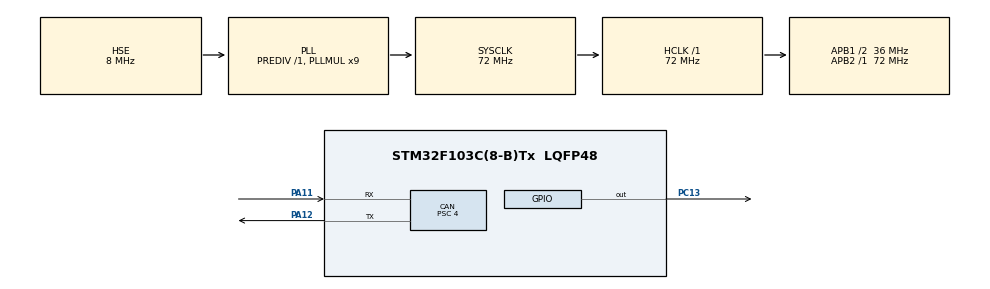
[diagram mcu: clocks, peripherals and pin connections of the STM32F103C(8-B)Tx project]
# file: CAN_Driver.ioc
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CAN.BS1=CAN_BS1_6TQ
CAN.BS2=CAN_BS2_2TQ
CAN.CalculateBaudRate=1000000
CAN.CalculateTimeBit=1000
CAN.CalculateTimeQuantum=111.11111111111111
CAN.Mode=CAN_MODE_NORMAL
CAN.Prescaler=4
CAN.TTCM=DISABLE
Mcu.Family=STM32F1
Mcu.Name=STM32F103C(8-B)Tx
Mcu.Package=LQFP48
NVIC.CAN1_RX1_IRQn=true\:0\:0\:false\:false\:true\:true\:true\:true
NVIC.PriorityGroup=NVIC_PRIORITYGROUP_4
NVIC.USB_LP_CAN1_RX0_IRQn=true\:1\:0\:true\:false\:true\:true\:true\:true
PA11.Mode=CAN_Activate
PA11.Signal=CAN_RX
PA12.Mode=CAN_Activate
PA12.Signal=CAN_TX
PA13.Mode=Serial_Wire
PA13.Signal=SYS_JTMS-SWDIO
PA14.Mode=Serial_Wire
PA14.Signal=SYS_JTCK-SWCLK
PC13-TAMPER-RTC.PinState=GPIO_PIN_SET
PC13-TAMPER-RTC.Signal=GPIO_Output
PD0-OSC_IN.Mode=HSE-External-Oscillator
PD0-OSC_IN.Signal=RCC_OSC_IN
PD1-OSC_OUT.Mode=HSE-External-Oscillator
PD1-OSC_OUT.Signal=RCC_OSC_OUT
ProjectManager.HeapSize=0x200
ProjectManager.StackSize=0x400
ProjectManager.TargetToolchain=MDK-ARM V5.32
RCC.AHBFreq_Value=72000000
RCC.APB1CLKDivider=RCC_HCLK_DIV2
RCC.APB1Freq_Value=36000000
RCC.APB1TimFreq_Value=72000000
RCC.APB2Freq_Value=72000000
RCC.APB2TimFreq_Value=72000000
RCC.HCLKFreq_Value=72000000
RCC.PLLMUL=RCC_PLL_MUL9
RCC.PLLSourceVirtual=RCC_PLLSOURCE_HSE
RCC.SYSCLKFreq_VALUE=72000000
RCC.SYSCLKSource=RCC_SYSCLKSOURCE_PLLCLK
RCC.USBFreq_Value=72000000
board=custom

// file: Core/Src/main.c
/* USER CODE BEGIN Header */
/**
  ******************************************************************************
  * @file           : main.c
  * @brief          : Main program body
  ******************************************************************************
  * @attention
  *
  * Copyright (c) 2025 STMicroelectronics.
  * All rights reserved.
  *
  * This software is licensed under terms that can be found in the LICENSE file
  * in the root directory of this software component.
  * If no LICENSE file comes with this software, it is provided AS-IS.
  *
  ******************************************************************************
  */
/* USER CODE END Header */
#include "main.h"
#include "can.h"
#include "gpio.h"

void SystemClock_Config(void);

/* USER CODE BEGIN 0 */
uint8_t flag=1;
float move,move_sum;
uint8_t tx_data[8]={1,2,3,4,5,6,7,8};
uint8_t rx_data[8]={0};
int16_t change=1;
int16_t target_angle=360;
struct Speed
{
  int16_t speed;
  volatile float Kp, Ki, Kd, Real, Out, Err0, Err1, ErrInt;
  volatile float Want;
};
struct Angle
{
  float angle,lastangle;
  volatile float Kp, Ki, Kd, Real, Out, Err0, Err1, ErrInt;
  volatile float Want;
};

struct Speed Speed_ctrl = {
  .speed = 0,
  .Kp = 8.4,
  .Ki = 1.2,
  .Kd = 30,
  .Real = 0,
  .Out = 0,
  .Err0 = 0,
  .Err1 = 0,
  .ErrInt = 0,
  .Want = 0
};

struct Angle Angle_ctrl = {
  .angle = 0,
  .lastangle = 0,
  .Kp = 10,
  .Ki = 0,
  .Kd = 5,
  .Real = 0,
  .Out = 0,
  .Err0 = 0,
  .Err1 = 0,
  .ErrInt = 0,
  .Want = 0
};

/* USER CODE END 0 */

int main(void)
{

  /* MCU Configuration--------------------------------------------------------*/

  /* Reset of all peripherals, Initializes the Flash interface and the Systick. */
  HAL_Init();

  /* Configure the system clock */
  SystemClock_Config();

  /* Initialize all configured peripherals */
  MX_GPIO_Init();
  MX_CAN_Init();
  /* USER CODE BEGIN 2 */
  // 在CAN初始化后启用FIFO0中断
if (HAL_CAN_ActivateNotification(&hcan, CAN_IT_RX_FIFO0_MSG_PENDING) != HAL_OK)
{
    Error_Handler();
}
if (HAL_CAN_ActivateNotification(&hcan, CAN_IT_RX_FIFO1_MSG_PENDING) != HAL_OK)
{
    Error_Handler();
}
  /* USER CODE END 2 */
  HAL_Delay(100);
  /* Infinite loop */
  /* USER CODE BEGIN WHILE */
  Angle_ctrl.Want=-720;
  while (1)
  {
    // if(Angle_ctrl.lastangle-Angle_ctrl.angle<-350)
    // {
    //   Angle_ctrl.Want+=360;
    // }

    /* USER CODE END WHILE */

  }
}

void SystemClock_Config(void)
{
  RCC_OscInitTypeDef RCC_OscInitStruct = {0};
  RCC_ClkInitTypeDef RCC_ClkInitStruct = {0};

  /** Initializes the RCC Oscillators according to the specified parameters
  * in the RCC_OscInitTypeDef structure.
  */
  RCC_OscInitStruct.OscillatorType = RCC_OSCILLATORTYPE_HSE;
  RCC_OscInitStruct.HSEState = RCC_HSE_ON;
  RCC_OscInitStruct.HSEPredivValue = RCC_HSE_PREDIV_DIV1;
  RCC_OscInitStruct.HSIState = RCC_HSI_ON;
  RCC_OscInitStruct.PLL.PLLState = RCC_PLL_ON;
  RCC_OscInitStruct.PLL.PLLSource = RCC_PLLSOURCE_HSE;
  RCC_OscInitStruct.PLL.PLLMUL = RCC_PLL_MUL9;
  if (HAL_RCC_OscConfig(&RCC_OscInitStruct) != HAL_OK)
  {
    Error_Handler();
  }

  /** Initializes the CPU, AHB and APB buses clocks
  */
  RCC_ClkInitStruct.ClockType = RCC_CLOCKTYPE_HCLK|RCC_CLOCKTYPE_SYSCLK
                              |RCC_CLOCKTYPE_PCLK1|RCC_CLOCKTYPE_PCLK2;
  RCC_ClkInitStruct.SYSCLKSource = RCC_SYSCLKSOURCE_PLLCLK;
  RCC_ClkInitStruct.AHBCLKDivider = RCC_SYSCLK_DIV1;
  RCC_ClkInitStruct.APB1CLKDivider = RCC_HCLK_DIV2;
  RCC_ClkInitStruct.APB2CLKDivider = RCC_HCLK_DIV1;

  if (HAL_RCC_ClockConfig(&RCC_ClkInitStruct, FLASH_LATENCY_2) != HAL_OK)
  {
    Error_Handler();
  }
}

/* USER CODE BEGIN 4 */
//FIFO0接收中断回调
void HAL_CAN_RxFifo0MsgPendingCallback(CAN_HandleTypeDef *hcan)
{
  if(My_CAN_Receive(rx_data)==8)
  {
    //外环角度环
    Angle_ctrl.lastangle=Angle_ctrl.angle;
    Angle_ctrl.angle=(float)(rx_data[0]<<8|rx_data[1]);
    Angle_ctrl.angle=(Angle_ctrl.angle*360.0)/8191.0;
    move=Angle_ctrl.angle-Angle_ctrl.lastangle;
    if(move<=-350)
    {
      move+=360;
    }
    if(move>=350)
    {
      move-=360;
    }
    move_sum+=move;
		//获取实际值
    Angle_ctrl.Real= move_sum;
		Angle_ctrl.Err0= Angle_ctrl.Err1;
		Angle_ctrl.Err1= Angle_ctrl.Want- Angle_ctrl.Real;
		Angle_ctrl.ErrInt +=  Angle_ctrl.Err0;
    //积分限幅
    //...
		 Angle_ctrl.Out= Angle_ctrl.Kp* Angle_ctrl.Err1+ Angle_ctrl.Ki* Angle_ctrl.ErrInt+ Angle_ctrl.Kd*( Angle_ctrl.Err1- Angle_ctrl.Err0);
		//输出限幅
		if( Angle_ctrl.Out>=200)
		{
			 Angle_ctrl.Out=200;
		}
		if( Angle_ctrl.Out<=-200)
		{
			 Angle_ctrl.Out=-200;
		}
		//把Out输出，进行调控
    // if(Angle_ctrl.lastangle-Angle_ctrl.angle>350)
    // {
    //   Angle_ctrl.angle=360;
    // }
    Speed_ctrl.Want=Angle_ctrl.Out;

    //内环速度环
    Speed_ctrl.speed=(int16_t)(rx_data[2]<<8|rx_data[3]);
		//获取实际值
    Speed_ctrl.Real=Speed_ctrl.speed;
		Speed_ctrl.Err0=Speed_ctrl.Err1;
		Speed_ctrl.Err1=Speed_ctrl.Want-Speed_ctrl.Real;
		Speed_ctrl.ErrInt += Speed_ctrl.Err0;
    //积分限幅
    if(Speed_ctrl.ErrInt>=100)
    {
      Speed_ctrl.ErrInt=100;
    }
    if(Speed_ctrl.ErrInt<=-100)
    {
      Speed_ctrl.ErrInt=-100;
    }
		Speed_ctrl.Out=Speed_ctrl.Kp*Speed_ctrl.Err1+Speed_ctrl.Ki*Speed_ctrl.ErrInt+Speed_ctrl.Kd*(Speed_ctrl.Err1-Speed_ctrl.Err0);
		//输出限幅
		if( Angle_ctrl.Out>=100)
		{
			 Angle_ctrl.Out=100;
		}
		if( Angle_ctrl.Out<=-100)
		{
			 Angle_ctrl.Out=-100;
		}
		My_CAN_Sete((int16_t) Speed_ctrl.Out);
  }

}
/* USER CODE END 4 */

void Error_Handler(void)
{
  __disable_irq();
  while (1)
  {
  }
}
